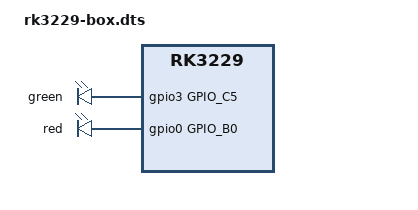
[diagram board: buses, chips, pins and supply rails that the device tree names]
/dts-v1/;

#include "rk3229.dtsi"
#include "rk322x-sdk.dtsi"

/ {
	wireless-wlan {
		wifi_chip_type = "rtl8189es";
	};

	wireless-bluetooth {
		status = "disabled";
	};

	power-led {
		compatible = "gpio-leds";
		green {
			gpios = <&gpio3 GPIO_C5 GPIO_ACTIVE_HIGH>;
			default-state = "on";
		};
		red {
			gpios = <&gpio0 GPIO_B0 GPIO_ACTIVE_HIGH>;
			default-state = "off";
		};
	};
};

&clk_core_dvfs_table {
	operating-points = <
		/* KHz    uV */
		408000	950000
		600000	975000
		816000	1000000
		1008000	1175000
		1200000	1275000
		1296000	1325000
		1392000	1350000
		1464000	1350000
		>;
	status = "okay";
};
